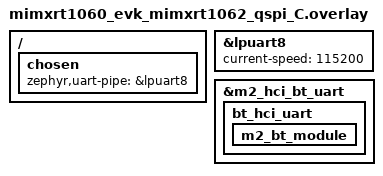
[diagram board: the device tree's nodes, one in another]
/*
 * Copyright 2025 NXP
 *
 * SPDX-License-Identifier: Apache-2.0
 */

/ {
	chosen {
		zephyr,uart-pipe = &lpuart8;
	};
};

/* Enable LPUART8 */
&lpuart8 {
	status = "okay";
	current-speed = <115200>;
};

&m2_hci_bt_uart {
	bt_hci_uart: bt_hci_uart {
	 m2_bt_module: m2_bt_module {
		/delete-property/ sdio-reset-gpios;
		/delete-property/ w-disable-gpios;
		};
	};
};
